# STM32N657 register map
File version: 1.0
CPU: CM55 r0p1, little endian, no MPU, FPU, vendor SysTick, 8 interrupt priority bits
Registers are 32-bit, read-write, reset 0x0 unless marked. A register's access mark holds for its fields unless they carry their own. Offsets are from the block's base; [hi:lo] are bit positions; {n}, {i} and the like mark numbered series.

## SYSCFG — System configuration controller
Base 0x46008000
Same registers: SYSCFG_S 0x56008000
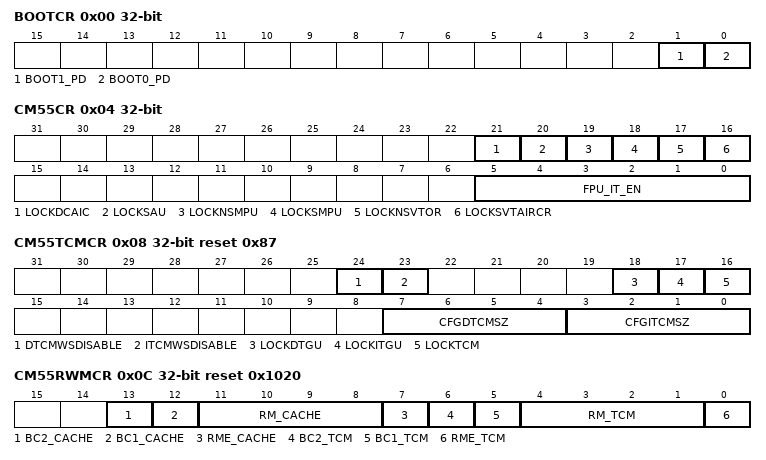
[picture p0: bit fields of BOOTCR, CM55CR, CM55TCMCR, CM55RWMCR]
0x00 BOOTCR — SYSCFG boot pin control register
  [1] BOOT1_PD — BOOT1 pin pull-down disable
  [0] BOOT0_PD — BOOT0 pin pull-down disable
0x04 CM55CR — SYSCFG Cortex-M55 control register
  [21] LOCKDCAIC — Disable access to the instruction cache direct cache access registers DCAICLR and DCAICRR.
  [20] LOCKSAU — Prevent changes to secure SAU memory regions already programmed.
  [19] LOCKNSMPU — Prevent changes to non-secure MPU memory regions already programmed.
  [18] LOCKSMPU — Prevent changes to programmed secure MPU memory regions.
  [17] LOCKNSVTOR — Prevent changes to the non-secure vector table base address.
  [16] LOCKSVTAIRCR — Prevent changes to:
  [5:0] FPU_IT_EN — Enable FPU exception
0x08 CM55TCMCR reset 0x87 — SYSCFG Cortex-M55 TCM control register
  [24] DTCMWSDISABLE — Disable wait-state applied by default on extended DTCM memory.
  [23] ITCMWSDISABLE — Disable wait-state applied by default on extended ITCM memory.
  [18] LOCKDTGU — Disable writes to registers associated with the DTCM interface security gating.
  [17] LOCKITGU — Disable writes to registers associated with the ITCM interface security gating.
  [16] LOCKTCM — Disable writes to registers associated with the TCM region
  [7:4] CFGDTCMSZ — Select DTCM memory size
  [3:0] CFGITCMSZ — Select ITCM memory size
0x0C CM55RWMCR reset 0x1020 — SYSCFG Cortex-CM55 memory RW margin register
  [13] BC2_CACHE — Biasing level adjust input recommended for Vnom + 10%
  [12] BC1_CACHE — Biasing level adjust input recommended for Vnom.
  [11:8] RM_CACHE — External read/write (RW) margin inputs for caches memories
  [7] RME_CACHE — RW margin enable input for caches memories
  [6] BC2_TCM — Biasing level adjust input recommended for Vnom + 10%
  [5] BC1_TCM — Biasing level adjust input recommended for Vnom
  [4:1] RM_TCM — External RW margin inputs for TCM memories
  [0] RME_TCM — RW margin enable input for TCM memories
0x10 INITSVTORCR reset 0x18000000 — SYSCFG Cortex-M55 SVTOR control register
  [31:7] SVTOR_ADDR — Secure vector table base address
0x14 INITNSVTORCR reset 0x8000000 — SYSCFG Cortex-M55 NSVTOR control register
  [31:7] NSVTOR_ADDR — Non-secure vector table base address
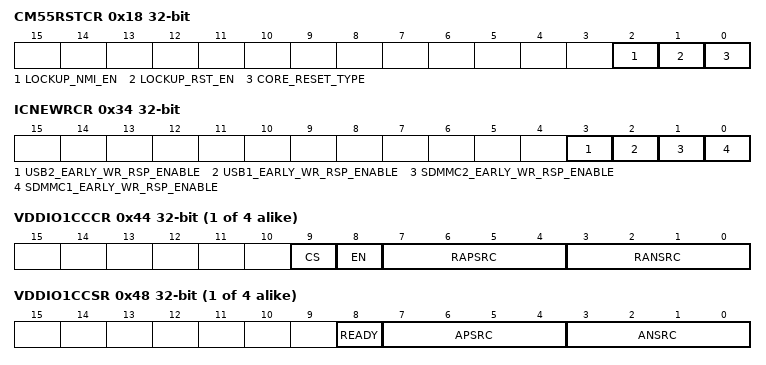
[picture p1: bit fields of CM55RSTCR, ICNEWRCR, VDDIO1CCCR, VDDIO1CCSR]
0x18 CM55RSTCR — SYSCFG Cortex-M55 reset type control register
  [2] LOCKUP_NMI_EN — Select action to perform on a lockup state on the core
  [1] LOCKUP_RST_EN — Select action to perform on a lockup state on the core
  [0] CORE_RESET_TYPE — Select reset to apply on core upon SYSRESETREQ
0x1C CM55PAHBWPR — SYSCFG Cortex-M55 P-AHB write posting control register
  [0] PAHB_ERROR_ACK — Error capture in write posting buffer
0x20 VENCRAMCR — SYSCFG VENCRAM control register
  [0] VENCRAM_EN — VENCRAM allocation VENC if active, or to system (if VENC inactive)
0x24 POTTAMPRSTCR — SYSCFG potential tamper reset register
  [0] POTTAMPERSETMASK — This bit can be set by software to mask PKA, SAES, CRYP1/2, and HASH reset, in case of potential tamper.
0x34 ICNEWRCR — SYSCFG AHB-AXI bridge early write response control register
  [3] USB2_EARLY_WR_RSP_ENABLE, [2] USB1_EARLY_WR_RSP_ENABLE, [1] SDMMC2_EARLY_WR_RSP_ENABLE, [0] SDMMC1_EARLY_WR_RSP_ENABLE
0x38 ICNCGCR — SYSCFG ICN clock gating control register
  [31:0] ICNCGCR — When bit[i] is set to 1, ICN clock gating[i] is OFF.
0x3C ICNBWRCR — SYSCFG ICN bandwidth regulator control register
  [31:0] ICNBWRCR — Bandwidth regulator control bits
0x40 IOCR — SYSCFG /O control register
  [31:0] IOCR — Digital or analog pins
{0x3C+8i} VDDIO{i}CCCR (i=1..4) — SYSCFG VDDIO{i} compensation cell control register
  [9] CS — Selects the code to be applied for the compensation cell of I/Os supplied by VDDIOx.
  [8] EN — Enables the compensation cell of I/Os supplied by VDDIOx.
  [7:4] RAPSRC — These bits are written by software to define an I/O compensation code for PMOS transistors. This code is applied to the I/O compensation cell when CS = 1.
  [3:0] RANSRC — These bits are written by software to define an I/O compensation code for NMOS transistors. This code is applied to the I/O compensation cell when the CS = 1.
{0x40+8i} VDDIO{i}CCSR ro (i=1..4) — SYSCFG VDDIO{i} compensation cell status register
  [8] READY — Provides the compensation cell status of I/Os supplied by VDDIOx
  [7:4] APSRC — This value is provided by the cell, and can be used by the CPU to compute an I/O compensation cell code for PMOS transistors.
  [3:0] ANSRC — This value is provided by the cell, and can be used by the CPU to compute an I/O compensation cell code for NMOS transistors.
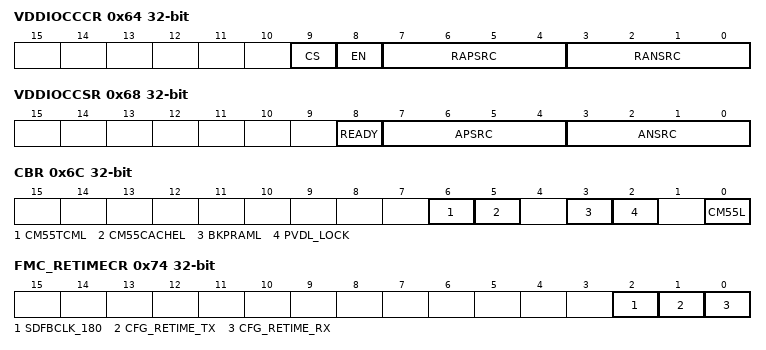
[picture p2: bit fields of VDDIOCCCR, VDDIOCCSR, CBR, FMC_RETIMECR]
0x64 VDDIOCCCR — SYSCFG VDDIO compensation cell control register
  [9] CS — Selects the code to be applied for the compensation cell of I/Os supplied by VDDIO.
  [8] EN — Enables the compensation cell of I/Os supplied by VDDIO.
  [7:4] RAPSRC — These bits are written by software to define an I/O compensation code for PMOS transistors. This code is applied to the I/O compensation cell when CS = 1.
  [3:0] RANSRC — These bits are written by software to define an I/O compensation code for NMOS transistors. This code is applied to the I/O compensation cell when CS = 1.
0x68 VDDIOCCSR ro — SYSCFG VDDIO compensation cell status register
  [8] READY — Provides the compensation cell status of I/Os supplied by VDDIO
  [7:4] APSRC — This value is provided by the cell, and can be used by the CPU to compute an I/O compensation cell code for PMOS transistors.
  [3:0] ANSRC — This value is provided by the cell, and can be used by the CPU to compute an I/O compensation cell code for NMOS transistors.
0x6C CBR — SYSCFG control timer break register
  [6] CM55TCML — CM55 TCM double ECC error lock
  [5] CM55CACHEL — CM55 cache double ECC error lock
  [3] BKPRAML — Backup SRAM double ECC error lock
  [2] PVDL_LOCK — PVD lock enable
  [0] CM55L — CM55 lockup lock enable
0x70 SEC_AIDCR reset 0x1 — SYSCFG DMA CID secure control register
  [2:0] DMACID_SEC — Secure OS allocates specific CID to DMA channel through these bits.
0x74 FMC_RETIMECR — SYSCFG FMC retiming logic control register
  [2] SDFBCLK_180 — Delay on feedback clock
  [1] CFG_RETIME_TX — Retiming on Tx path
  [0] CFG_RETIME_RX — Retiming on Rx path
0x78 NPU_ICNCR — SYSCFG NPU RAM interleaving control register
  [0] INTERLEAVING_ACTIVE — Control interleaving on NPU RAMs
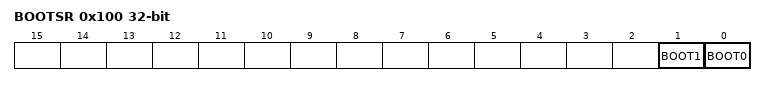
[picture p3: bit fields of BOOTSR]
0x100 BOOTSR ro — SYSCFG boot pin status register
  [1] BOOT1 — BOOT1 pin value
  [0] BOOT0 — BOOT0 pin value
0x104 AHBWP_ERROR_SR ro — SYSCFG AHB write posting address error register
  [31:0] PAHB_ERROR_ADDR — Reports address of the first error in P-AHB write-posting buffer
0x400 SMPSHDPCR — SYSCFG SMPS observable signals through HDP selection configuration register
  [3:0] SMPSHDPSEL — Others: Reserved
0x800 NONSEC_AIDCR reset 0x1 — SYSCFG DMA CID non-secure control register
  [2:0] DMACID_NONSEC — Non-secure OS allocates specific CID to DMA channel through these bits
